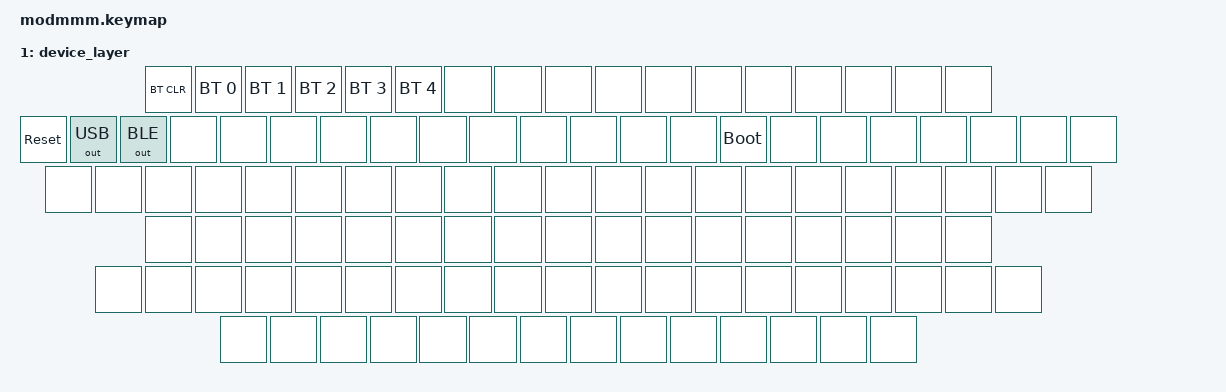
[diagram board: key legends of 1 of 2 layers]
/*
 * Copyright (c) 2020 The ZMK Contributors
 *
 * SPDX-License-Identifier: MIT
 */

#include <behaviors.dtsi>
#include <dt-bindings/zmk/keys.h>
#include <dt-bindings/zmk/bt.h>
#include <dt-bindings/zmk/outputs.h>

/ {
    keymap {
        compatible = "zmk,keymap";

        default_layer {
            bindings = <
    &kp ESC  &kp F1  &kp F2  &kp F3  &kp F4     &kp F5  &kp F6  &kp F7  &kp F8     &kp F9  &kp F10  &kp F11  &kp F12            &kp PSCRN  &kp SLCK  &mo 1
    &kp GRAVE &kp N1 &kp N2 &kp N3 &kp N4 &kp N5 &kp N6 &kp N7 &kp  N8  &kp  N9 &kp  N0  &kp MINUS &kp EQUAL &none &kp BSPC     &kp INS    &kp HOME  &kp PG_UP  &kp KP_NLCK  &kp KP_DIVIDE  &kp KP_MULTIPLY  &kp KP_MINUS
    &kp TAB         &kp Q  &kp W  &kp E  &kp R  &kp T  &kp Y  &kp U  &kp   I   &kp  O  &kp   P  &kp LBKT &kp RBKT  &kp BSLH     &kp DEL    &kp END   &kp PG_DN  &kp KP_N7    &kp KP_N8      &kp KP_N9        &kp KP_PLUS
    &kp CLCK         &kp A  &kp S  &kp D  &kp F  &kp G  &kp H  &kp J  &kp   K   &kp  L  &kp SEMI &kp SQT           &kp RET                                      &kp KP_N4    &kp KP_N5      &kp KP_N6        &none
    &kp LSHFT &none   &kp Z  &kp X  &kp C  &kp V  &kp B  &kp N  &kp M  &kp COMMA &kp DOT &kp FSLH           &none &kp RSHFT               &kp UP                &kp KP_N1    &kp KP_N2      &kp KP_N3        &kp KP_ENTER
    &kp LCTRL &kp LALT                    &kp BSPC  &kp SPACE  &kp RGUI                                  &kp RALT  &kp RCTRL    &kp LEFT  &kp DOWN &kp RIGHT    &kp KP_N0    &none          &kp KP_DOT       &none
            >;
        };
        
        device_layer {
            bindings = <
    &bt BT_CLR    &bt BT_SEL 0 &bt BT_SEL 1 &bt BT_SEL 2 &bt BT_SEL 3 &bt BT_SEL 4   &none &none &none &none   &none &none &none &none      &none &none &none
    &sys_reset &out OUT_USB &out OUT_BLE &none &none  &none    &none    &none    &none    &none    &none    &none   &none &none &bootloader &none &none &none    &none &none &none &none
    &none           &none    &none    &none    &none    &none    &none    &none    &none    &none    &none    &none    &none     &none      &none &none &none    &none &none &none &none
    &none            &none    &none    &none    &none    &none    &none    &none    &none    &none    &none    &none             &none                           &none &none &none &none
    &none &none        &none    &none    &none    &none    &none    &none    &none    &none    &none    &none              &none &none            &none          &none &none &none &none
    &none     &none                             &none     &none    &none                                               &none     &none      &none &none &none    &none &none &none &none
            >;
        };

    };
};
